# HT32F1654 register map
Vendor: Holtek Semiconductor; Series: HT32F1xxx; File version: 1.0
CPU: CM3 r2p0, little endian, VTOR, 4 interrupt priority bits, 69 interrupts
Registers are 32-bit, read-write, reset 0x0 unless marked. A register's access mark holds for its fields unless they carry their own. Offsets are from the block's base; [hi:lo] are bit positions; {n}, {i} and the like mark numbered series.

## GPIOA
Base 0x400B0000
Same registers: GPIOB 0x400B2000, GPIOC 0x400B4000, GPIOD 0x400B6000
0x00 DIRCR
  [15:0] DIR
0x04 INER
  [15:0] INEN
0x08 PUR
  [15:0] PU
0x0C PDR
  [15:0] PD
0x10 ODR
  [15:0] OD
0x14 DRVR
  [7:0] DV
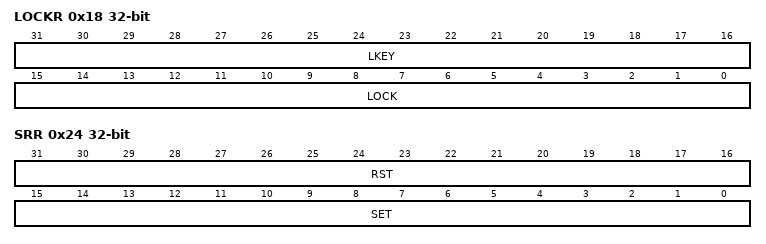
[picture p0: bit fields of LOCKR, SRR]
0x18 LOCKR
  [31:16] LKEY, [15:0] LOCK
0x1C DINR
  [15:0] DIN
0x20 DOUTR
  [15:0] DOUT
0x24 SRR
  [31:16] RST, [15:0] SET
0x28 RR
  [15:0] RST

## AFIO
Base 0x40022000
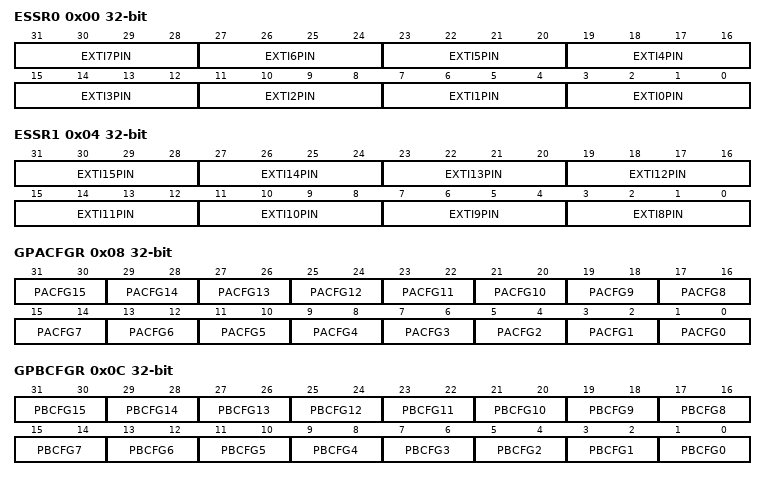
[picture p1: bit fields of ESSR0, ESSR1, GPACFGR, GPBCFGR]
0x00 ESSR0
  [4n+3:4n] EXTI{n}PIN (n=0..7)
0x04 ESSR1
  [4n-29:4n-32] EXTI{n}PIN (n=8..15)
0x08 GPACFGR
  [2n+1:2n] PACFG{n} (n=0..15)
0x0C GPBCFGR
  [2n+1:2n] PBCFG{n} (n=0..15)
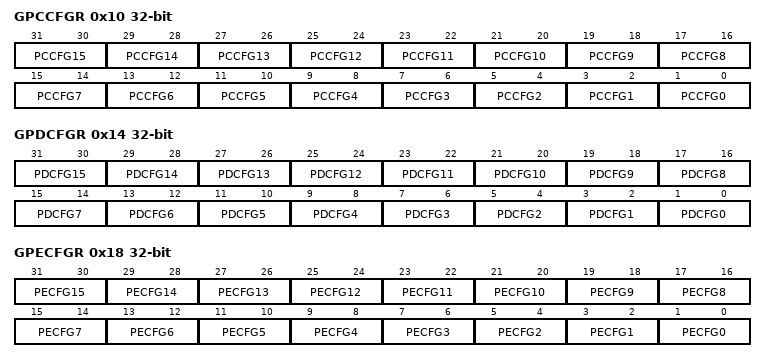
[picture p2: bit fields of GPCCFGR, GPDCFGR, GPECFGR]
0x10 GPCCFGR
  [2n+1:2n] PCCFG{n} (n=0..15)
0x14 GPDCFGR
  [2n+1:2n] PDCFG{n} (n=0..15)
0x18 GPECFGR
  [2n+1:2n] PECFG{n} (n=0..15)

## EXTI
Base 0x40024000
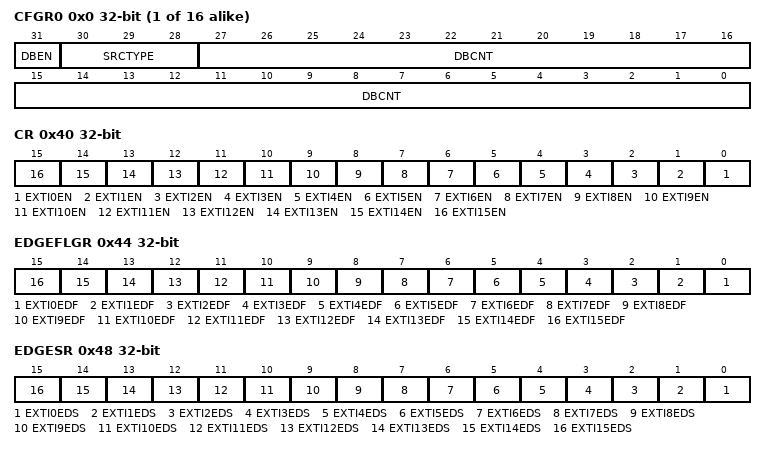
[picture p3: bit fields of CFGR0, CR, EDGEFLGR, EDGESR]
{0x0+4i} CFGR{i} (i=0..15)
  [31] DBEN, [30:28] SRCTYPE, [27:0] DBCNT
0x40 CR
  [n] EXTI{n}EN (n=0..15)
0x44 EDGEFLGR
  [n] EXTI{n}EDF (n=0..15)
0x48 EDGESR
  [n] EXTI{n}EDS (n=0..15)
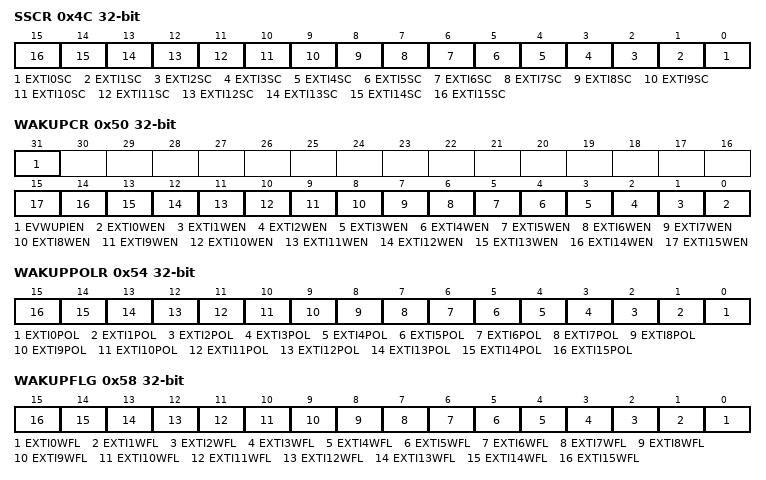
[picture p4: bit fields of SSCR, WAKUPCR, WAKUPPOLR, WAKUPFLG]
0x4C SSCR
  [n] EXTI{n}SC (n=0..15)
0x50 WAKUPCR
  [31] EVWUPIEN, [n] EXTI{n}WEN (n=0..15)
0x54 WAKUPPOLR
  [n] EXTI{n}POL (n=0..15)
0x58 WAKUPFLG
  [n] EXTI{n}WFL (n=0..15)

## ADC
Base 0x40010000
0x04 RST
  [0] ADRST
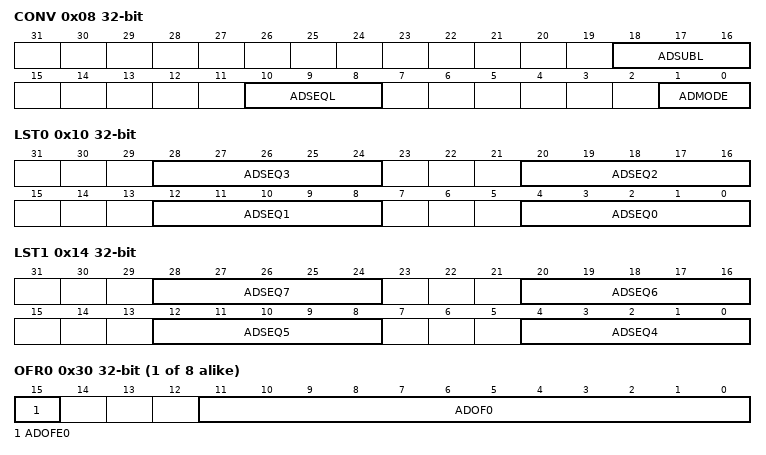
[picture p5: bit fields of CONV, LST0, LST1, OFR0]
0x08 CONV
  [18:16] ADSUBL, [10:8] ADSEQL, [1:0] ADMODE
0x10 LST0
  [8n+4:8n] ADSEQ{n} (n=0..3)
0x14 LST1
  [8n-28:8n-32] ADSEQ{n} (n=4..7)
{0x30+4i} OFR{i} (i=0..7)
  [15] ADOFE{i}, [11:0] ADOF{i}
{0x70+4i} STR{i} (i=0..7)
  [7:0] ADST{i}
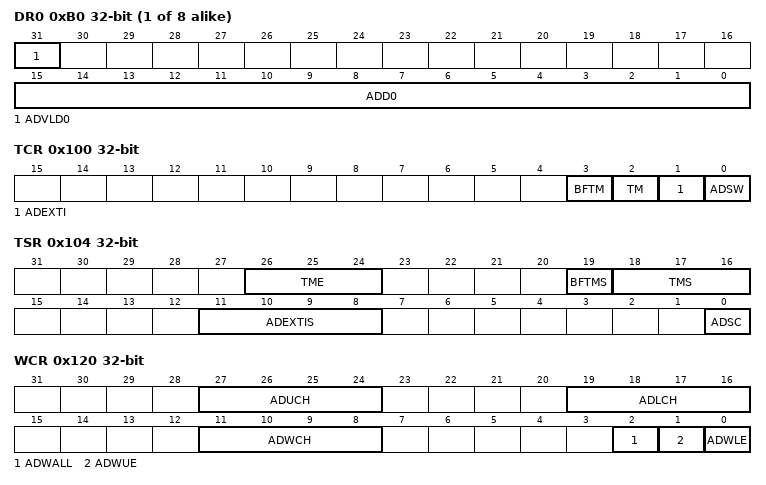
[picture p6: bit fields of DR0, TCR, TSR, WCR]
{0xB0+4i} DR{i} (i=0..7)
  [31] ADVLD{i}, [15:0] ADD{i}
0x100 TCR
  [3] BFTM, [2] TM, [1] ADEXTI, [0] ADSW
0x104 TSR
  [26:24] TME, [19] BFTMS, [18:16] TMS, [11:8] ADEXTIS, [0] ADSC
0x120 WCR
  [27:24] ADUCH, [19:16] ADLCH, [11:8] ADWCH, [2] ADWALL, [1] ADWUE, [0] ADWLE
0x124 LTR
  [11:0] ADLT
0x128 UTR
  [11:0] ADUT
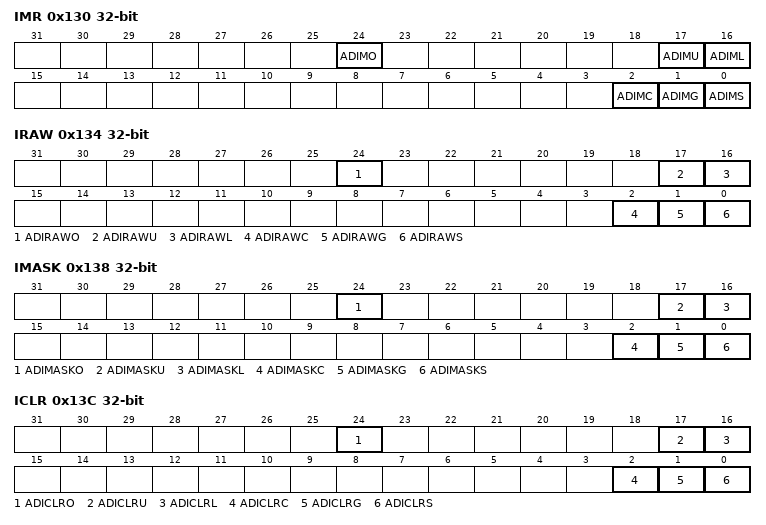
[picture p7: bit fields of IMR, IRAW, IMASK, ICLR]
0x130 IMR
  [24] ADIMO, [17] ADIMU, [16] ADIML, [2] ADIMC, [1] ADIMG, [0] ADIMS
0x134 IRAW
  [24] ADIRAWO, [17] ADIRAWU, [16] ADIRAWL, [2] ADIRAWC, [1] ADIRAWG, [0] ADIRAWS
0x138 IMASK
  [24] ADIMASKO, [17] ADIMASKU, [16] ADIMASKL, [2] ADIMASKC, [1] ADIMASKG, [0] ADIMASKS
0x13C ICLR
  [24] ADICLRO, [17] ADICLRU, [16] ADICLRL, [2] ADICLRC, [1] ADICLRG, [0] ADICLRS
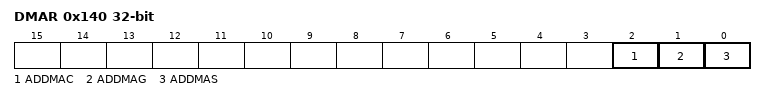
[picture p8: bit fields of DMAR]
0x140 DMAR
  [2] ADDMAC, [1] ADDMAG, [0] ADDMAS

## GPTM0
Base 0x4006E000
Same registers: GPTM1 0x4006F000
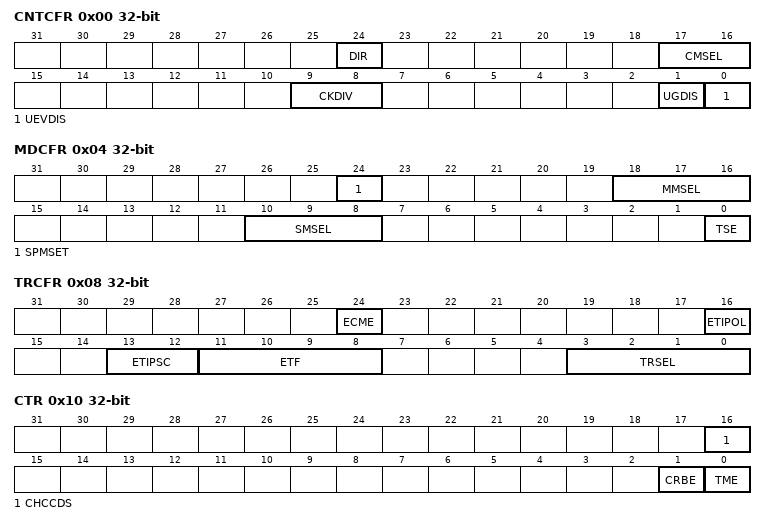
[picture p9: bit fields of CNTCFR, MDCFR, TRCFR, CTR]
0x00 CNTCFR
  [24] DIR, [17:16] CMSEL, [9:8] CKDIV, [1] UGDIS, [0] UEVDIS
0x04 MDCFR
  [24] SPMSET, [18:16] MMSEL, [10:8] SMSEL, [0] TSE
0x08 TRCFR
  [24] ECME, [16] ETIPOL, [13:12] ETIPSC, [11:8] ETF, [3:0] TRSEL
0x10 CTR
  [16] CHCCDS, [1] CRBE, [0] TME
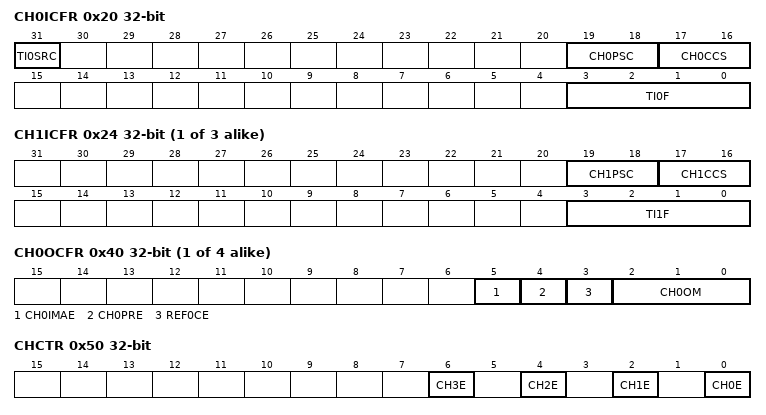
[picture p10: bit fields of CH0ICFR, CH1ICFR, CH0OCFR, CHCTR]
0x20 CH0ICFR
  [31] TI0SRC, [19:18] CH0PSC, [17:16] CH0CCS, [3:0] TI0F
{0x20+4i} CH{i}ICFR (i=1..3)
  [19:18] CH{i}PSC, [17:16] CH{i}CCS, [3:0] TI{i}F
{0x40+4i} CH{i}OCFR (i=0..3)
  [5] CH{i}IMAE, [4] CH{i}PRE, [3] REF{i}CE, [2:0] CH{i}OM
0x50 CHCTR
  [2n] CH{n}E (n=0..3)
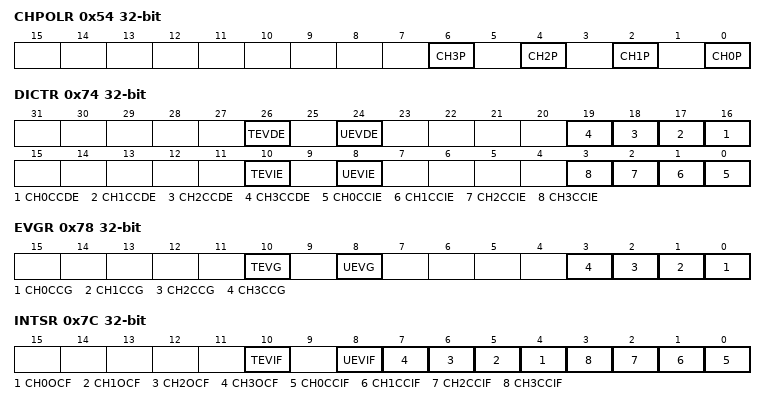
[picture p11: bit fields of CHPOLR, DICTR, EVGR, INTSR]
0x54 CHPOLR
  [2n] CH{n}P (n=0..3)
0x74 DICTR
  [26] TEVDE, [24] UEVDE, [n+16] CH{n}CCDE (n=0..3), [10] TEVIE, [8] UEVIE, [n] CH{n}CCIE (n=0..3)
0x78 EVGR
  [10] TEVG, [8] UEVG, [n] CH{n}CCG (n=0..3)
0x7C INTSR
  [10] TEVIF, [8] UEVIF, [n+4] CH{n}OCF (n=0..3), [n] CH{n}CCIF (n=0..3)
0x80 CNTR
  [15:0] CNTV
0x84 PSCR
  [15:0] PSCV
0x88 CRR
  [15:0] CRV
{0x90+4i} CH{i}CCR (i=0..3)
  [15:0] CH{i}CCV
{0x90+4i} CH{i}ACR (i=0..3)
  [15:0] CH{i}ACV

## BFTM0
Base 0x40076000
Same registers: BFTM1 0x40077000
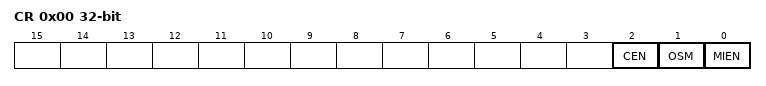
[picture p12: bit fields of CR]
0x00 CR
  [2] CEN, [1] OSM, [0] MIEN
0x04 SR
  [0] MIF
0x08 CNTR
0x0C CMPR reset 0xFFFFFFFF
  [31:0] CMP

## MCTM0
Base 0x4002C000
Same registers: MCTM1 0x4002D000
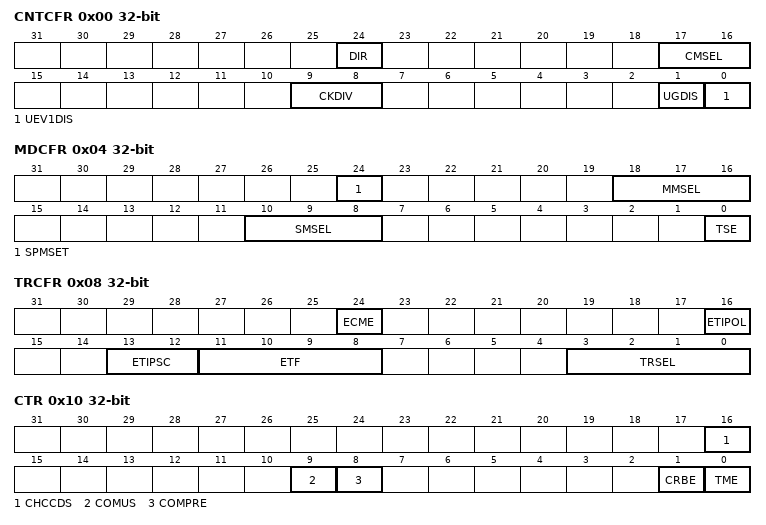
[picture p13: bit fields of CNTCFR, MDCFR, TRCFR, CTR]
0x00 CNTCFR
  [24] DIR, [17:16] CMSEL, [9:8] CKDIV, [1] UGDIS, [0] UEV1DIS
0x04 MDCFR
  [24] SPMSET, [18:16] MMSEL, [10:8] SMSEL, [0] TSE
0x08 TRCFR
  [24] ECME, [16] ETIPOL, [13:12] ETIPSC, [11:8] ETF, [3:0] TRSEL
0x10 CTR
  [16] CHCCDS, [9] COMUS, [8] COMPRE, [1] CRBE, [0] TME
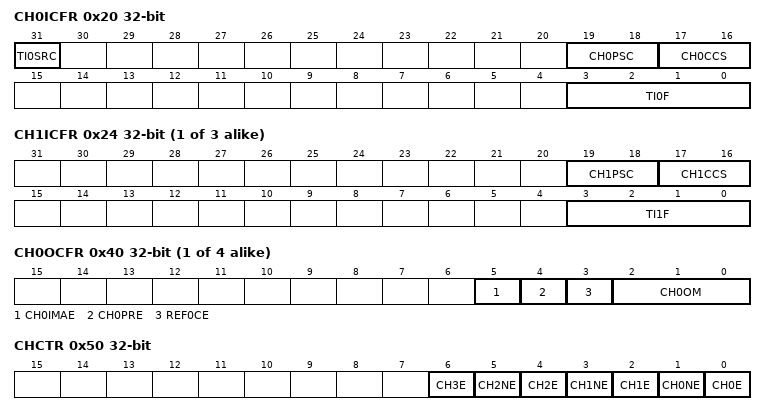
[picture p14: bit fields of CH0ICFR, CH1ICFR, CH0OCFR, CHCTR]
0x20 CH0ICFR
  [31] TI0SRC, [19:18] CH0PSC, [17:16] CH0CCS, [3:0] TI0F
{0x20+4i} CH{i}ICFR (i=1..3)
  [19:18] CH{i}PSC, [17:16] CH{i}CCS, [3:0] TI{i}F
{0x40+4i} CH{i}OCFR (i=0..3)
  [5] CH{i}IMAE, [4] CH{i}PRE, [3] REF{i}CE, [2:0] CH{i}OM
0x50 CHCTR
  [2n] CH{n}E (n=0..3), [5] CH2NE, [3] CH1NE, [1] CH0NE
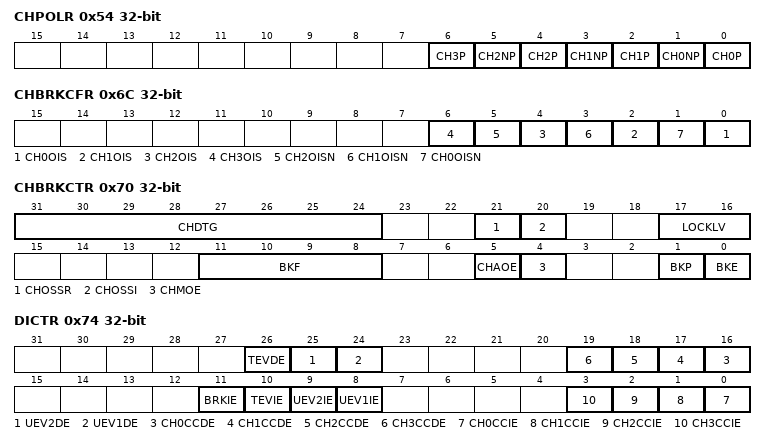
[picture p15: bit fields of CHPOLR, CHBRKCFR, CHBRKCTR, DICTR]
0x54 CHPOLR
  [2n] CH{n}P (n=0..3), [5] CH2NP, [3] CH1NP, [1] CH0NP
0x6C CHBRKCFR
  [2n] CH{n}OIS (n=0..3), [5] CH2OISN, [3] CH1OISN, [1] CH0OISN
0x70 CHBRKCTR
  [31:24] CHDTG, [21] CHOSSR, [20] CHOSSI, [17:16] LOCKLV, [11:8] BKF, [5] CHAOE, [4] CHMOE, [1] BKP, [0] BKE
0x74 DICTR
  [26] TEVDE, [25] UEV2DE, [24] UEV1DE, [n+16] CH{n}CCDE (n=0..3), [11] BRKIE, [10] TEVIE, [9] UEV2IE, [8] UEV1IE, [n] CH{n}CCIE (n=0..3)
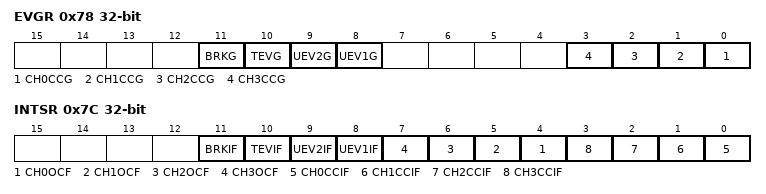
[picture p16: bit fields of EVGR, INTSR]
0x78 EVGR
  [11] BRKG, [10] TEVG, [9] UEV2G, [8] UEV1G, [n] CH{n}CCG (n=0..3)
0x7C INTSR
  [11] BRKIF, [10] TEVIF, [9] UEV2IF, [8] UEV1IF, [n+4] CH{n}OCF (n=0..3), [n] CH{n}CCIF (n=0..3)
0x80 CNTR
  [15:0] CNTV
0x84 PSCR
  [15:0] PSCV
0x88 CRR
  [15:0] CRV
0x8C REPR
  [7:0] REPV
{0x90+4i} CH{i}CCR (i=0..3)
  [15:0] CH{i}CCV
